# nrf54lc10a_application register map
Vendor: Nordic Semiconductor; Series: nrf54l; File version: 1
CPU: CM33 r0p4, little endian, MPU, FPU, 3 interrupt priority bits, 270 interrupts, 4 SAU regions
Registers are 32-bit, read-write, reset 0x0 unless marked. A register's access mark holds for its fields unless they carry their own. Offsets are from the block's base; [hi:lo] are bit positions; lines under a group give offsets from that group; {n}, {i} and the like mark numbered series; 'fields as' and 'values as' point back to an identical list.

## GLOBAL_CRACENCORE_S — CRACENCORE
Base 0x50010000
0x00 CRYPTMSTRDMA group — Unspecified
  0x00 FETCHADDRLSB — Fetch Address Least Significant Word
    [31:0] FETCHADDRLSB — Address
  0x04 FETCHADDRMSB — Fetch Address Most Significant Word
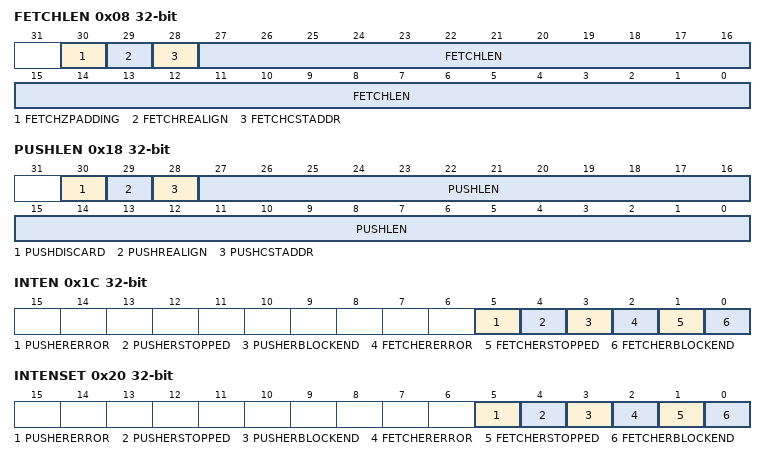
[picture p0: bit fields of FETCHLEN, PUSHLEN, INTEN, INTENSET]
  0x08 FETCHLEN — Fetch DMA Length (only used in direct mode)
    [30] FETCHZPADDING
    [29] FETCHREALIGN — Realign length
    [28] FETCHCSTADDR — Constant address
    [27:0] FETCHLEN — Length of data block
  0x0C FETCHTAG — Fetch User Tag (only used in direct mode)
    [31:0] FETCHTAG — User tag
  0x10 PUSHADDRLSB — Push Address Least Significant Word
    [31:0] PUSHADDRLSB — Address
  0x14 PUSHADDRMSB — Push Address Most Significant Word
  0x18 PUSHLEN — Push Length (only used in direct mode)
    [30] PUSHDISCARD — Discard data
    [29] PUSHREALIGN — Realign length
    [28] PUSHCSTADDR — Constant address
    [27:0] PUSHLEN — Length of data block
  0x1C INTEN — Interrupt Enable mask
    [5] PUSHERERROR — Bus error during pusher DMA access
    [4] PUSHERSTOPPED — Pusher DMA reached the end of a block with Stop=1, or end of direct transfer
    [3] PUSHERBLOCKEND — Pusher DMA reached the end of a block (if enabled in the descriptor; scatter-gather only)
    [2] FETCHERERROR — Bus error during fetcher DMA access
    [1] FETCHERSTOPPED — Fetcher DMA reached the end of a block with Stop=1, or end of direct transfer
    [0] FETCHERBLOCKEND — Fetcher DMA reached the end of a block (if enabled in the descriptor; scatter-gather only)
  0x20 INTENSET — Interrupt Set
    [5] PUSHERERROR wo — Bus error during pusher DMA access
    [4] PUSHERSTOPPED wo — Pusher DMA reached the end of a block with Stop=1, or end of direct transfer
    [3] PUSHERBLOCKEND wo — Pusher DMA reached the end of a block (if enabled in the descriptor; scatter-gather only)
    [2] FETCHERERROR wo — Bus error during fetcher DMA access
    [1] FETCHERSTOPPED wo — Fetcher DMA reached the end of a block with Stop=1, or end of direct transfer
    [0] FETCHERBLOCKEND wo — Fetcher DMA reached the end of a block (if enabled in the descriptor; scatter-gather only)
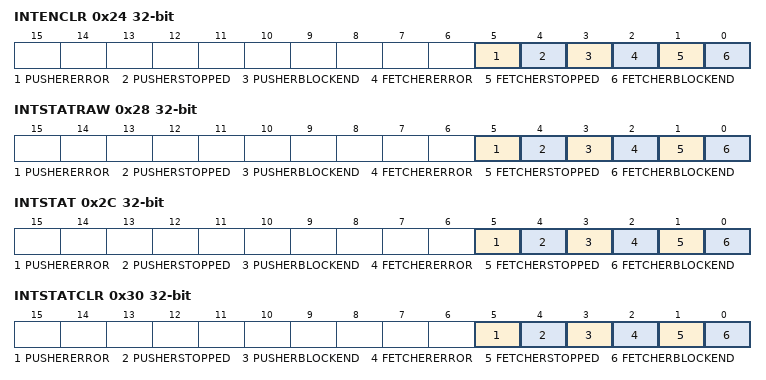
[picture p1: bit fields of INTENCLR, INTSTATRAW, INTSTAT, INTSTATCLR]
  0x24 INTENCLR — Interrupt Clear
    fields as CRYPTMSTRDMA.INTENSET
  0x28 INTSTATRAW — Interrupt Status Raw
    [5] PUSHERERROR ro — Bus error during pusher DMA access
    [4] PUSHERSTOPPED ro — Pusher DMA reached the end of a block with Stop=1, or end of direct transfer
    [3] PUSHERBLOCKEND ro — Pusher DMA reached the end of a block (if enabled in the descriptor; scatter-gather only)
    [2] FETCHERERROR ro — Bus error during fetcher DMA access
    [1] FETCHERSTOPPED ro — Fetcher DMA reached the end of a block with Stop=1, or end of direct transfer
    [0] FETCHERBLOCKEND ro — Fetcher DMA reached the end of a block (if enabled in the descriptor; scatter-gather only)
  0x2C INTSTAT — Interrupt Status
    fields as CRYPTMSTRDMA.INTSTATRAW
  0x30 INTSTATCLR — Interrupt Status Clear
    fields as CRYPTMSTRDMA.INTENSET
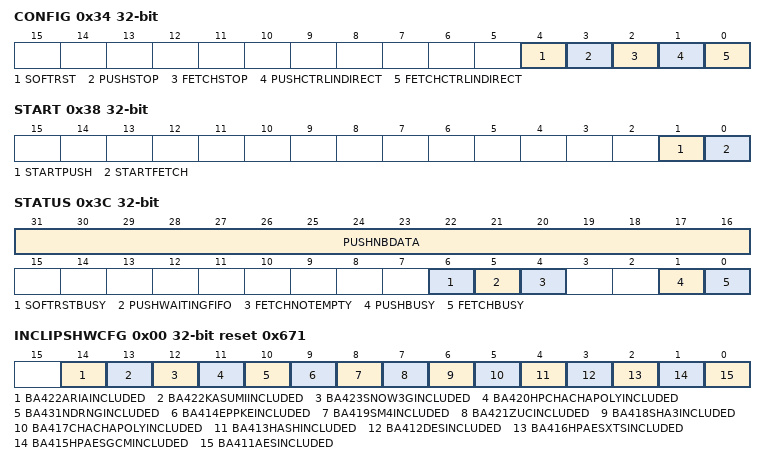
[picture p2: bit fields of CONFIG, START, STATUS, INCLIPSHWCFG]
  0x34 CONFIG — Cryptomaster configuration
    [4] SOFTRST — Soft reset the cryptomaster.
    [3] PUSHSTOP — Stop pusher DMA.
    [2] FETCHSTOP — Stop fetcher.
    [1] PUSHCTRLINDIRECT — Pusher scatter/gather.
    [0] FETCHCTRLINDIRECT — Fetcher scatter/gather.
  0x38 START
    [1] STARTPUSH wo — Writing a '1' starts the pusher DMA. Writing a '0' has no effect.
    [0] STARTFETCH wo — Writing a '1' starts the fetcher DMA. Writing a '0' has no effect.
  0x3C STATUS
    [31:16] PUSHNBDATA ro — Amount of data in the pusher DMA output FIFO
    [6] SOFTRSTBUSY ro — This bit is high when the soft reset is on going
    [5] PUSHWAITINGFIFO ro — Pusher DMA Waiting FIFO. This bit is high when the pusher is waiting for more data in output FIFO.
    [4] FETCHNOTEMPTY ro — Not empty flag for fetcher DMA input FIFO
    [1] PUSHBUSY ro — This bit is high as long as the pusher DMA is busy.
    [0] FETCHBUSY ro — This bit is high as long as the fetcher DMA is busy.
0x400 CRYPTMSTRHW group — Unspecified
  0x00 INCLIPSHWCFG reset 0x671 — Incuded IPs Hardware configuration
    [14] BA422ARIAINCLUDED ro — Generic g_IncludeAria value.
    [13] BA422KASUMIINCLUDED ro — Generic g_IncludeKasumi value.
    [12] BA423SNOW3GINCLUDED ro — Generic g_IncludeSnow3G value.
    [11] BA420HPCHACHAPOLYINCLUDED ro — Generic g_IncludeHPChachaPoly value.
    [10] BA431NDRNGINCLUDED ro — Generic g_IncludeNDRNG value.
    [9] BA414EPPKEINCLUDED ro — Generic g_IncludePKE value.
    [8] BA419SM4INCLUDED ro — Generic g_IncludeSM4 value.
    [7] BA421ZUCINCLUDED ro — Generic g_IncludeZUC value.
    [6] BA418SHA3INCLUDED ro — Generic g_IncludeSHA3 value.
    [5] BA417CHACHAPOLYINCLUDED ro — Generic g_IncludeChachaPoly value.
    [4] BA413HASHINCLUDED ro — Generic g_IncludeHASH value.
    [3] BA412DESINCLUDED ro — Generic g_IncludeDES value.
    [2] BA416HPAESXTSINCLUDED ro — Generic g_IncludeAESXTS value.
    [1] BA415HPAESGCMINCLUDED ro — Generic g_IncludeAESGCM value.
    [0] BA411AESINCLUDED ro — Generic g_IncludeAES value.
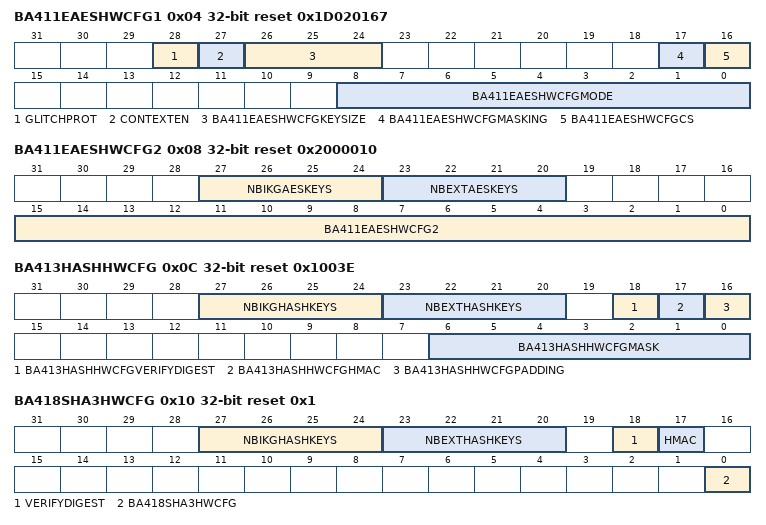
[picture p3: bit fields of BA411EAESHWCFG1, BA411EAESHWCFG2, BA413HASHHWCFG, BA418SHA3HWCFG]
  0x04 BA411EAESHWCFG1 reset 0x1D020167 — Generic g_AesModesPoss value.
    [28] GLITCHPROT ro — Generic g_GlitchProtection value.
    [27] CONTEXTEN ro — Generic g_CxSwitch value.
    [26:24] BA411EAESHWCFGKEYSIZE ro — Generic g_Keysize value.
    [17] BA411EAESHWCFGMASKING ro — Generic g_UseMasking value.
    [16] BA411EAESHWCFGCS ro — Generic g_CS value.
    [8:0] BA411EAESHWCFGMODE ro — Generic g_AesModesPoss value.
  0x08 BA411EAESHWCFG2 reset 0x2000010 — Generic g_CtrSize value.
    [27:24] NBIKGAESKEYS ro — Generic g_IKG_nb_AES_keys value.
    [23:20] NBEXTAESKEYS ro — Generic g_Ext_nb_AES_keys value.
    [15:0] BA411EAESHWCFG2 ro — Maximum size in bits for the counter in CTR and CCM modes (g_CtrSize value).
  0x0C BA413HASHHWCFG reset 0x1003E — Generic g_Hash value
    [27:24] NBIKGHASHKEYS ro — Generic g_IKG_nb_Hash_keys value.
    [23:20] NBEXTHASHKEYS ro — Generic g_Ext_nb_Hash_keys value.
    [18] BA413HASHHWCFGVERIFYDIGEST ro — Generic g_HashVerifyDigest value.
    [17] BA413HASHHWCFGHMAC ro — Generic g_HMAC_enabled value.
    [16] BA413HASHHWCFGPADDING ro — Generic g_HashPadding value.
    [6:0] BA413HASHHWCFGMASK ro — Generic g_HashMaskFunc value.
  0x10 BA418SHA3HWCFG reset 0x1 — Generic g_Sha3CtxtEn value.
    [27:24] NBIKGHASHKEYS ro — Number of SHA3 IKG keys.
    [23:20] NBEXTHASHKEYS ro — Number of SHA3 HW keys.
    [18] VERIFYDIGEST ro — Support to digest verification.
    [17] HMAC ro — HMAC enabled.
    [0] BA418SHA3HWCFG ro — Generic g_Sha3CtxtEn value.
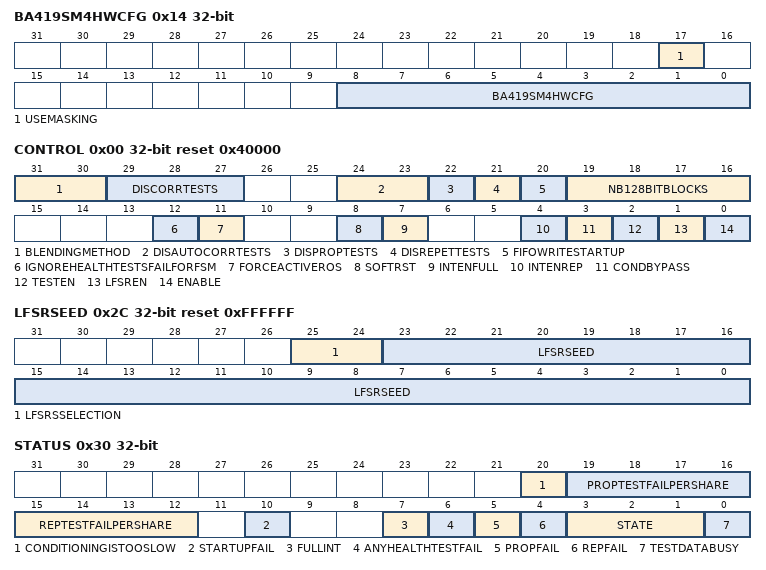
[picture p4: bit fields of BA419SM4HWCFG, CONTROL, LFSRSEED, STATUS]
  0x14 BA419SM4HWCFG — Generic g_SM4ModesPoss value.
    [17] USEMASKING ro — Generic g_sm4UseMasking value.
    [8:0] BA419SM4HWCFG ro — Generic g_SM4ModesPoss value.
  0x18 BA424ARIAHWCFG — Generic g_aria_modePoss value.
    [8:0] BA424ARIAHWCFG ro
0x1000 RNGCONTROL group — Unspecified
  0x00 CONTROL reset 0x40000
    [31:30] BLENDINGMETHOD — Select blending method
      0=CONCATENATION; 1=XORLEVEL1; 2=XORLEVEL2; 3=VONNEUMANN (VON-NEUMANN debiasing)
    [29:27] DISCORRTESTS — Disable specific delay(s) check in correlation test - different ROs:
    [24:23] DISAUTOCORRTESTS — Disable specific delay(s) check in auto-correlation test - same RO:
    [22] DISPROPTESTS — All proportion tests (each share) are disabled via this single bit.
    [21] DISREPETTESTS — All repetition tests (each share) are disabled via this single bit.
    [20] FIFOWRITESTARTUP — Enable write of the samples in the FIFO during start-up.
    [19:16] NB128BITBLOCKS — Number of 128 bit blocks used in conditioning (AES-CBC-MAC) post-processing.
    [12] IGNOREHEALTHTESTSFAILFORFSM — Results of the health tests during start-up and online test do not affect the control FSM state.
    [11] FORCEACTIVEROS — Force oscillators to run when FIFO is full.
    [8] SOFTRST — Datapath content flush and control FSM
    [7] INTENFULL — Enable interrupt if FIFO is full.
    [4] INTENREP — Enable interrupt if any of the health test fails.
    [3] CONDBYPASS — Conditioning function bypass.
      0=NORMAL (the conditioning function is used (normal mode).); 1=BYPASS (the conditioning function is bypassed (to observe entropy source directly).)
    [2] TESTEN — Select input for conditioning function and continuous tests:
      0=NORMAL (Noise source (normal mode).); 1=TEST (Test data register (test mode).)
    [1] LFSREN — Select between the NDRNG with asynchronous free running oscillators (when 0) and the Pseudo-Random generator with synchronous oscillators for simulation purpose (when 1).
    [0] ENABLE wo — Start the NDRNG. Self-clearing bit.
  0x04 FIFOLEVEL
    [31:0] FIFOLEVEL — Number of 32 bits words of random values available in the FIFO.
  0x08 FIFOTHRESHOLD reset 0x3
    [2:0] FIFOTHRESHOLD — FIFO level threshold below which the module leaves the idle state to refill the FIFO. Expressed in number of 128bit blocks.
  0x0C FIFODEPTH reset 0x10
    [31:0] FIFODEPTH ro — Maximum number of 32 bits words that can be stored in the FIFO.
  {0x10+4j} KEY[{j}] (j=0..3) — Description collection: Key register.
    [31:0] KEY
  0x20 TESTDATA
    [31:0] TESTDATA wo
  0x24 REPEATTHRESHOLD reset 0x4 — Repetition test cut-off register.
    [5:0] REPEATTHRESHOLD — Repetition Test cut-off value.
  0x28 PROPTESTCUTOFF reset 0xD — Proportion test cut-off register.
    [8:0] PROPTESTCUTOFF — Proportion test cut-off value.
  0x2C LFSRSEED reset 0xFFFFFF
    [25:24] LFSRSSELECTION wo — Share index for which initialization value should be used.
    [23:0] LFSRSEED — LFSR initialization value.
  0x30 STATUS
    [20] CONDITIONINGISTOOSLOW write-0-clears — Conditioning consumes data slower than they are provided to it.
    [19:16] PROPTESTFAILPERSHARE ro — NIST Proportion test failure per share.
    [15:12] REPTESTFAILPERSHARE ro — NIST Repetition test failure per share.
    [10] STARTUPFAIL write-0-clears — Start-up test(s) failure.
    [7] FULLINT ro — FIFO full status.
    [6] ANYHEALTHTESTFAIL write-0-clears — Any of the enabled health tests is failing.
    [5] PROPFAIL ro — NIST proportion test(s) failure.
    [4] REPFAIL ro — NIST repetition test(s) failure.
    [3:1] STATE ro — State of the control FSM:
      0=RESET; 1=STARTUP; 2=IDLERON (Idle / FIFO full); 4=FILLFIFO; 5=ERROR
    [0] TESTDATABUSY ro — High when data written to TestData register is being processed.
  0x34 WARMUPPERIOD reset 0x200 — Number of clock cycles in warm-up sequence.
    [11:0] WARMUPPERIOD
  0x38 DISABLEOSC
    [31:0] DISABLEOSC — Disable oscillator rings.
  0x44 SAMPLINGPERIOD reset 0xFFF — Number of clock cycles between sampling moments.
    [11:0] SAMPLINGPERIOD
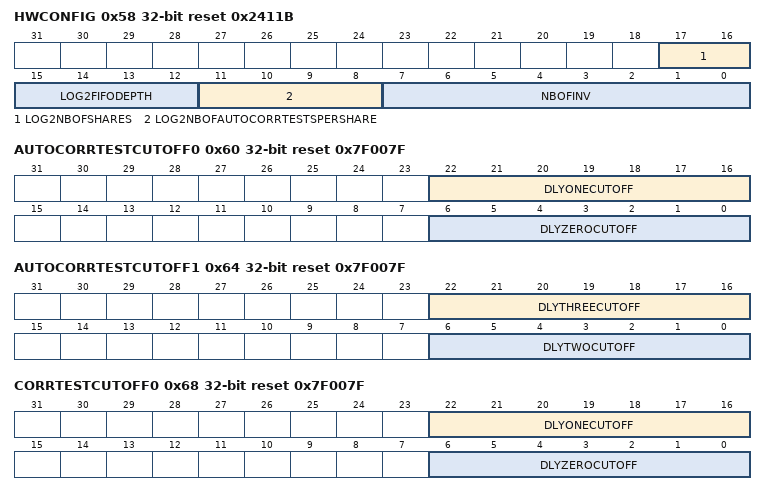
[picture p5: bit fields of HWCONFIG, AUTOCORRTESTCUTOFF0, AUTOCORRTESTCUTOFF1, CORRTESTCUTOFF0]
  0x58 HWCONFIG reset 0x2411B — Hardware configuration register.
    [17:16] LOG2NBOFSHARES ro — Generic g_Log2NbOfShares value.
    [15:12] LOG2FIFODEPTH ro — Generic g_Log2FifoDepth value.
    [11:8] LOG2NBOFAUTOCORRTESTSPERSHARE ro — Generic g_Log2NbOfAutoCorrTestsPerShare value.
    [7:0] NBOFINV ro — Generic g_NbOfInverters value.
  0x5C COOLDOWNPERIOD — Number of clock cycles in cool-down sequence.
    [11:0] COOLDOWNPERIOD
  0x60 AUTOCORRTESTCUTOFF0 reset 0x7F007F — AutoCorrTestCutoff register 0
    [22:16] DLYONECUTOFF — Auto-correlation test cut-off value for delay of +1 sample.
    [6:0] DLYZEROCUTOFF — Auto-correlation test cut-off value for delay of 0 samples.
  0x64 AUTOCORRTESTCUTOFF1 reset 0x7F007F — AutoCorrTestCutoff register 1
    [22:16] DLYTHREECUTOFF — Auto-correlation test cut-off value for delay of +3 samples.
    [6:0] DLYTWOCUTOFF — Auto-correlation test cut-off value for delay of +2 samples.
  0x68 CORRTESTCUTOFF0 reset 0x7F007F — CorrTestCutoff register 0
    [22:16] DLYONECUTOFF — Correlation test cut-off value for delay of +/-1 sample.
    [6:0] DLYZEROCUTOFF — Correlation test cut-off value for delay of 0 samples.
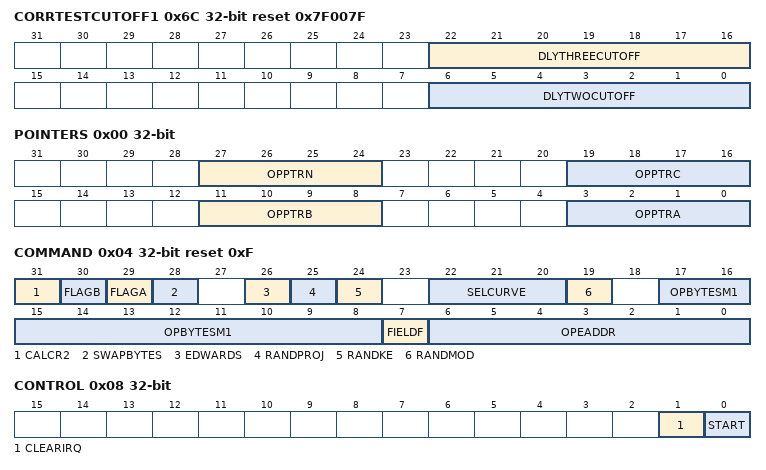
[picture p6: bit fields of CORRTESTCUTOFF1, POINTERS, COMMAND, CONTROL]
  0x6C CORRTESTCUTOFF1 reset 0x7F007F — CorrTestCutoff register 1
    [22:16] DLYTHREECUTOFF — Correlation test cut-off value for delay of +/- 3 samples.
    [6:0] DLYTWOCUTOFF — Correlation test cut-off value for delay of +/- 2 samples.
  0x70 AUTOCORRTESTFAILED — Auto-correlation test failing ring(s).
    [31:0] AUTOCORRTESTFAILED ro
  0x74 CORRTESTFAILED — Correlation test failing ring.
    [31:0] CORRTESTFAILED ro
  0x7C HWVERSION reset 0x1 — Fixed to 1 for this version.
    [31:0] HWVERSION ro
  {0x80+4j} FIFO[{j}] (j=0..31) ro — Description collection: FIFO data
    [31:0] DATA — FIFO data
0x2000 PK group — Unspecified
  0x00 POINTERS
    [27:24] OPPTRN — When executing primitive arithmetic operations, this pointer defines the location where the modulus is located in memory (location 0x0 to 0xF).
    [19:16] OPPTRC — When executing primitive arithmetic operations, this pointer defines the location (0x0 to 0xF) where the result will be stored in memory.
    [11:8] OPPTRB — When executing primitive arithmetic operations, this pointer defines where operand B is located in memory (location 0x0 to 0xF).
    [3:0] OPPTRA — When executing primitive arithmetic operations, this pointer defines where operand A is located in memory (location 0x0 to 0xF).
  0x04 COMMAND reset 0xF
    [31] CALCR2 — This bit indicates if the IP has to calculate R**2 mod N for the next operation.
      0=NRECALCULATE (don't recalculate R² mod N); 1=RECALCULATE (re-calculate R² mod N)
    [30] FLAGB
    [29] FLAGA
    [28] SWAPBYTES — Swap the bytes on AHB interface:
      0=NATIVE (Native format (little endian).); 1=SWAPPED (Byte swapped (big endian).)
    [26] EDWARDS — Enable Edwards curve.
    [25] RANDPROJ — Enable randomization of projective coordinates (counter-measure).
    [24] RANDKE — Enable randomization of exponent/scalar (counter-measure).
    [22:20] SELCURVE — Enable accelerator for specific curve modulus:
      0=NOACCEL (Unspecified); 1=P256 (Unspecified); 2=P384 (Unspecified); 3=P521 (Unspecified); 4=P192 (Unspecified); 5=CURVE25519 (Unspecified); 6=ED25519 (Unspecified)
    [19] RANDMOD — Enable randomization of modulus (counter-measure).
    [17:8] OPBYTESM1 — This field defines the size (= number of bytes minus one) of the operands for the current operation.
    [7] FIELDF — 0: Field is GF(p) 1: Field is GF(2**m)
    [6:0] OPEADDR — This field defines the operation to be performed.
  0x08 CONTROL — Command register.
    [1] CLEARIRQ wo — Writing a 1 clears the IRQ output.
    [0] START wo — Writing a 1 starts the processing.
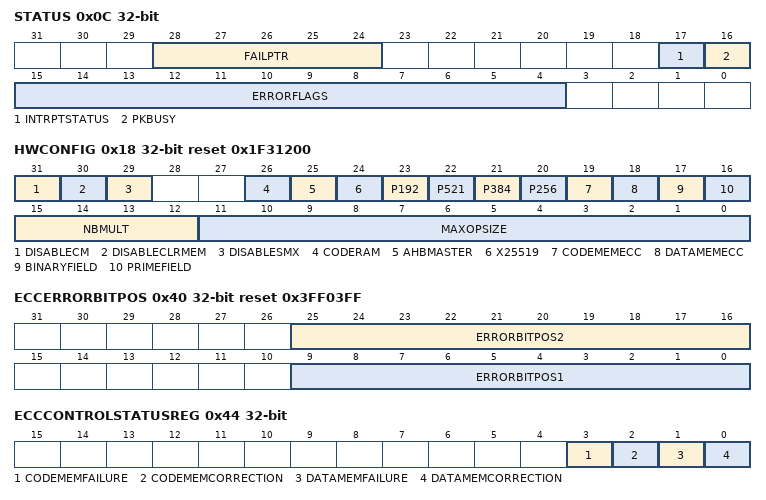
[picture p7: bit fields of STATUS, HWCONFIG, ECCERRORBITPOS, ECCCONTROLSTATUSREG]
  0x0C STATUS
    [28:24] FAILPTR ro — These bits indicate which data location generated the error flag.
    [17] INTRPTSTATUS ro — This bit reflects the IRQ output value.
    [16] PKBUSY ro — This bit reflects the BUSY output value.
    [15:4] ERRORFLAGS ro — These bits indicate an error condition.
  0x14 TIMER
    [31:1] TIMER — Number of clock cycles (as the number of core cycles is always even, register bit 0 is tied to zero).
  0x18 HWCONFIG reset 0x1F31200 — Hardware configuration register.
    [31] DISABLECM ro — State of DisableCM input (high when counter-measures are disabled).
    [30] DISABLECLRMEM ro — State of DisableClrMem input (high when automatic clear of the RAM after reset is disabled).
    [29] DISABLESMX ro — State of DisableSMx input (high when SM2/SM9 operations are disabled).
    [26] CODERAM ro — Code memory
      0=ROM (Code memory is a ROM.); 1=RAM (Code memory is a RAM.)
    [25] AHBMASTER ro — Memory access
      0=SLAVE (Memory access through AHB Slave and internally in the PKE.); 1=MASTER (Memory access through AHB Master, outside the PKE.)
    [24] X25519 ro — Support Curve25519/Ed25519 acceleration.
    [23] P192 ro — Support ECC P192 acceleration.
    [22] P521 ro — Support ECC P521 acceleration.
    [21] P384 ro — Support ECC P384 acceleration.
    [20] P256 ro — Support ECC P256 acceleration.
    [19] CODEMEMECC ro — Support code memory error correction.
    [18] DATAMEMECC ro — Support data memory error correction.
    [17] BINARYFIELD ro — Support binary field.
    [16] PRIMEFIELD ro — Support prime field.
    [15:12] NBMULT ro — Number of multipliers:
      0=MULT1 (1 multiplier); 1=MULT4 (4 multipliers); 2=MULT16 (16 multipliers); 4=MULT64 (64 multipliers); 8=MULT256 (256 multipliers)
    [11:0] MAXOPSIZE ro — Maximum operand size (number of bytes).
  0x1C OPSIZE reset 0x1000 — Operand size register.
    [12:0] OPSIZE — Operand size (number of bytes): This register is used when the memory is accessed via AHB Master
      0x100=256 bytes; 0x209=521 bytes; 0x800=2048 bytes; 0x1000=4096 bytes
  0x40 ECCERRORBITPOS reset 0x3FF03FF — ECC Error bit position register.
    [25:16] ERRORBITPOS2 — Position of error bit 2
    [9:0] ERRORBITPOS1 — Position of error bit 1
  0x44 ECCCONTROLSTATUSREG — ECC Control and Status register.
    [3] CODEMEMFAILURE write-1-clears — Code Memory Failure flag, clear on write
    [2] CODEMEMCORRECTION write-1-clears — Code Memory Correction flag, clear on write
    [1] DATAMEMFAILURE write-1-clears — Data Memory Failure flag, clear on write
    [0] DATAMEMCORRECTION write-1-clears — Data Memory Correction flag, clear on write
  0x78 MICROCODEFORMAT reset 0xD4B79DDA
    [31:0] MICROCODEFORMAT ro — Microcode format number.
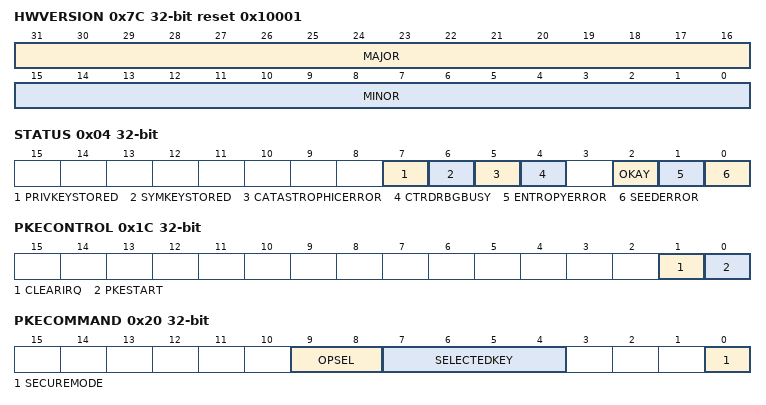
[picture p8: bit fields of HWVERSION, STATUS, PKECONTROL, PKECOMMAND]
  0x7C HWVERSION reset 0x10001 — Hardware Version register.
    [31:16] MAJOR ro — Major version number.
    [15:0] MINOR ro — Minor version number.
0x3000 IKG group — Unspecified
  0x00 START
    [0] START wo — Start the Isolated Key Generation.
  0x04 STATUS
    [7] PRIVKEYSTORED ro — Private Keys are stored.
    [6] SYMKEYSTORED ro — Symmetric Keys are stored.
    [5] CATASTROPHICERROR ro — Catastrophic error during CTR_DRBG health test (only when g_hw_health_test = true).
    [4] CTRDRBGBUSY ro — CTR_DRBG health test is busy (only when g_hw_health_test = true).
    [2] OKAY ro — Isolated Key Generation is okay.
    [1] ENTROPYERROR ro — Entropy Error during Isolated Key Generation.
    [0] SEEDERROR ro — Seed Error during Isolated Key Generation.
  0x08 INITDATA
    [0] INITDATA wo — Writing a 1 initialise Nonce and Personalisation_String registers counters, i.e. start writing from the 32 LSB.
  0x0C NONCE
    [31:0] NONCE — Nonce (write/read value 32-bit by 32-bit).
  0x10 PERSONALISATIONSTRING
    [31:0] PERSONALISATIONSTRING — Personalisation String (write/read value 32-bit by 32-bit).
  0x14 RESEEDINTERVALLSB reset 0x80000000
  0x18 RESEEDINTERVALMSB
    [15:0] RESEEDINTERVALMSB
  0x1C PKECONTROL
    [1] CLEARIRQ wo — Clear the IRQ output.
    [0] PKESTART wo — Start the PKE operation or trigger for Secure mode exit.
  0x20 PKECOMMAND
    [9:8] OPSEL — Select PKE operation with Isolated Key
      0=PUBKEY (Public Key Generation); 1=ECDSA (ECDSA Signature); 2=PTMUL (Point Multiplication)
    [7:4] SELECTEDKEY — Select Generated Private Key for PKE operation.
    [0] SECUREMODE
      0=DEACTIVATED (Unspecified); 1=ACTIVATED (Unspecified)
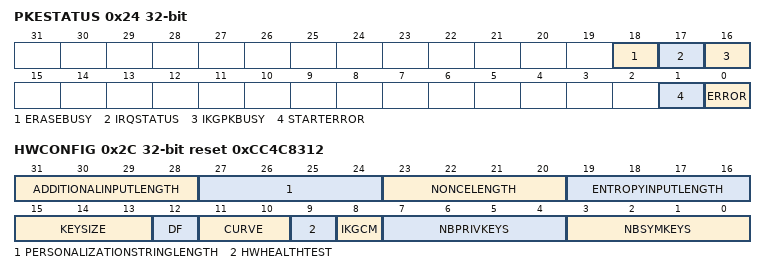
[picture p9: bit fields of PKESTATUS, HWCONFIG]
  0x24 PKESTATUS
    [18] ERASEBUSY ro — The PKE Data RAM is being erased.
    [17] IRQSTATUS ro — IRQ, set when the operation is finished and cleared when the CPU writes the bit 1 of PKE_Control Register or a new operation is started.
    [16] IKGPKBUSY ro — Busy, set when the operation starts and cleared when the operation is finished.
    [1] STARTERROR ro — Error because a new operation is started while the previous one is still busy.
    [0] ERROR ro — Error because either Private Keys are not stored or the operation is not defined.
  0x28 SOFTRST
    [0] SOFTRST — Software reset:
      0=NORMAL (Normal mode.); 1=KEY (The Isolated Key Generation logic and the keys are reset.)
  0x2C HWCONFIG reset 0xCC4C8312
    [31:28] ADDITIONALINPUTLENGTH ro — Value of g_additional_input_length/32.
    [27:24] PERSONALIZATIONSTRINGLENGTH ro — Value of g_personalization_string_length/32.
    [23:20] NONCELENGTH ro — Value of g_nonce_length/32.
    [19:16] ENTROPYINPUTLENGTH ro — Value of g_entropy_input_length/32.
    [15:13] KEYSIZE ro — AES Key Size support for the AES Core embedded in the CTR_DRBG.
      1=AES128 (supports AES128); 2=AES192 (supports AES192); 4=AES256 (supports AES256)
    [12] DF ro — Derivation function is implemented in the CTR_DRBG when 1.
    [11:10] CURVE ro — ECC curve for IKG (input).
      0=P256; 1=P384; 2=P521
    [9] HWHEALTHTEST ro — CTR_DRBG health test is implemented when 1.
    [8] IKGCM ro — Countermeasures for IKG operations are implemented when 1.
    [7:4] NBPRIVKEYS ro — Number of Private Keys generated.
    [3:0] NBSYMKEYS ro — Number of Symmetric Keys generated.

## Notices in the file
Copyright (c) 2010 - 2026, Nordic Semiconductor ASA All rights reserved.
SPDX-License-Identifier: BSD-3-Clause
Redistribution and use in source and binary forms, with or without
modification, are permitted provided that the following conditions are met:
1. Redistributions of source code must retain the above copyright notice, this
list of conditions and the following disclaimer.
2. Redistributions in binary form must reproduce the above copyright
notice, this list of conditions and the following disclaimer in the
documentation and/or other materials provided with the distribution.
3. Neither the name of Nordic Semiconductor ASA nor the names of its
contributors may be used to endorse or promote products derived from this
software without specific prior written permission.
THIS SOFTWARE IS PROVIDED BY THE COPYRIGHT HOLDERS AND CONTRIBUTORS "AS IS"
AND ANY EXPRESS OR IMPLIED WARRANTIES, INCLUDING, BUT NOT LIMITED TO, THE
IMPLIED WARRANTIES OF MERCHANTABILITY, AND FITNESS FOR A PARTICULAR PURPOSE
ARE DISCLAIMED. IN NO EVENT SHALL NORDIC SEMICONDUCTOR ASA OR CONTRIBUTORS BE
LIABLE FOR ANY DIRECT, INDIRECT, INCIDENTAL, SPECIAL, EXEMPLARY, OR
CONSEQUENTIAL DAMAGES (INCLUDING, BUT NOT LIMITED TO, PROCUREMENT OF
SUBSTITUTE GOODS OR SERVICES; LOSS OF USE, DATA, OR PROFITS; OR BUSINESS
INTERRUPTION) HOWEVER CAUSED AND ON ANY THEORY OF LIABILITY, WHETHER IN
CONTRACT, STRICT LIABILITY, OR TORT (INCLUDING NEGLIGENCE OR OTHERWISE)
ARISING IN ANY WAY OUT OF THE USE OF THIS SOFTWARE, EVEN IF ADVISED OF THE
POSSIBILITY OF SUCH DAMAGE.
